# ssi register map
Vendor: Texas Instruments
Peripheral module from a debugger description file (folder sc4cc231e6pm).
Registers are 32-bit, read-write, no defined reset value unless marked. A register's access mark holds for its fields unless they carry their own. Offsets are as the file gives them; lines under a group give offsets from that group; [hi:lo] are bit positions; {n}, {i} and the like mark numbered series; 'fields as' and 'values as' point back to an identical list; <NAME> marks a mode.

## SSI0 — SSI register offsets
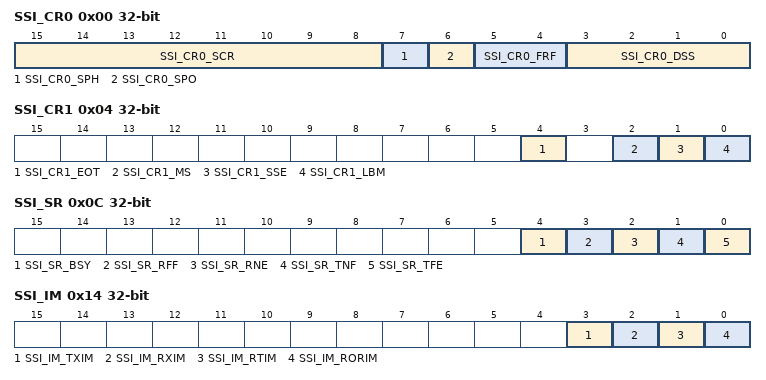
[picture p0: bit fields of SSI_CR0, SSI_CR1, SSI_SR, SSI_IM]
0x00 SSI_CR0 — SSI Control 0
  [15:8] SSI_CR0_SCR — SSI Serial Clock Rate
  [7] SSI_CR0_SPH — SSI Serial Clock Phase
  [6] SSI_CR0_SPO — SSI Serial Clock Polarity
  [5:4] SSI_CR0_FRF — SSI Frame Format Select
    0=SSI_CR0_FRF_MOTO (Freescale SPI Frame Format); 1=SSI_CR0_FRF_TI (Synchronous Serial Frame Format); 2=SSI_CR0_FRF_NMW (MICROWIRE Frame Format)
  [3:0] SSI_CR0_DSS — SSI Data Size Select
    {v}={v+1}-bit data (v=3..15)
0x04 SSI_CR1 — SSI Control 1
  [4] SSI_CR1_EOT — End of Transmission
  [2] SSI_CR1_MS — SSI Master/Slave Select
  [1] SSI_CR1_SSE — SSI Synchronous Serial Port Enable
  [0] SSI_CR1_LBM — SSI Loopback Mode
0x08 SSI_DR — SSI Data
  [15:0] SSI_DR_DATA — SSI Receive/Transmit Data
0x0C SSI_SR ro — SSI Status
  [4] SSI_SR_BSY — SSI Busy Bit
  [3] SSI_SR_RFF — SSI Receive FIFO Full
  [2] SSI_SR_RNE — SSI Receive FIFO Not Empty
  [1] SSI_SR_TNF — SSI Transmit FIFO Not Full
  [0] SSI_SR_TFE — SSI Transmit FIFO Empty
0x10 SSI_CPSR — SSI Clock Prescale
  [7:0] SSI_CPSR_CPSDVSR — SSI Clock Prescale Divisor
0x14 SSI_IM — SSI Interrupt Mask
  [3] SSI_IM_TXIM — SSI Transmit FIFO Interrupt Mask
  [2] SSI_IM_RXIM — SSI Receive FIFO Interrupt Mask
  [1] SSI_IM_RTIM — SSI Receive Time-Out Interrupt Mask
  [0] SSI_IM_RORIM — SSI Receive Overrun Interrupt Mask
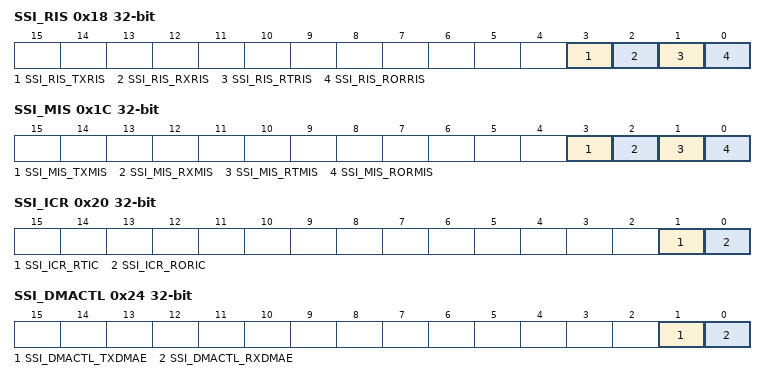
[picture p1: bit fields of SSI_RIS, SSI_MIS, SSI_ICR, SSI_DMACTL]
0x18 SSI_RIS ro — SSI Raw Interrupt Status
  [3] SSI_RIS_TXRIS — SSI Transmit FIFO Raw Interrupt Status
  [2] SSI_RIS_RXRIS — SSI Receive FIFO Raw Interrupt Status
  [1] SSI_RIS_RTRIS — SSI Receive Time-Out Raw Interrupt Status
  [0] SSI_RIS_RORRIS — SSI Receive Overrun Raw Interrupt Status
0x1C SSI_MIS ro — SSI Masked Interrupt Status
  [3] SSI_MIS_TXMIS — SSI Transmit FIFO Masked Interrupt Status
  [2] SSI_MIS_RXMIS — SSI Receive FIFO Masked Interrupt Status
  [1] SSI_MIS_RTMIS — SSI Receive Time-Out Masked Interrupt Status
  [0] SSI_MIS_RORMIS — SSI Receive Overrun Masked Interrupt Status
0x20 SSI_ICR wo — SSI Interrupt Clear
  [1] SSI_ICR_RTIC — SSI Receive Time-Out Interrupt Clear
  [0] SSI_ICR_RORIC — SSI Receive Overrun Interrupt Clear
0x24 SSI_DMACTL — SSI DMA Control
  [1] SSI_DMACTL_TXDMAE — Transmit DMA Enable
  [0] SSI_DMACTL_RXDMAE — Receive DMA Enable
0xFC8 SSI_CC — SSI Clock Configuration
  [3:0] SSI_CC_CS — SSI Baud Clock Source
    0=SSI_CC_CS_SYSPLL (System clock (based on clock source and divisor factor)); 5=SSI_CC_CS_PIOSC (PIOSC)
